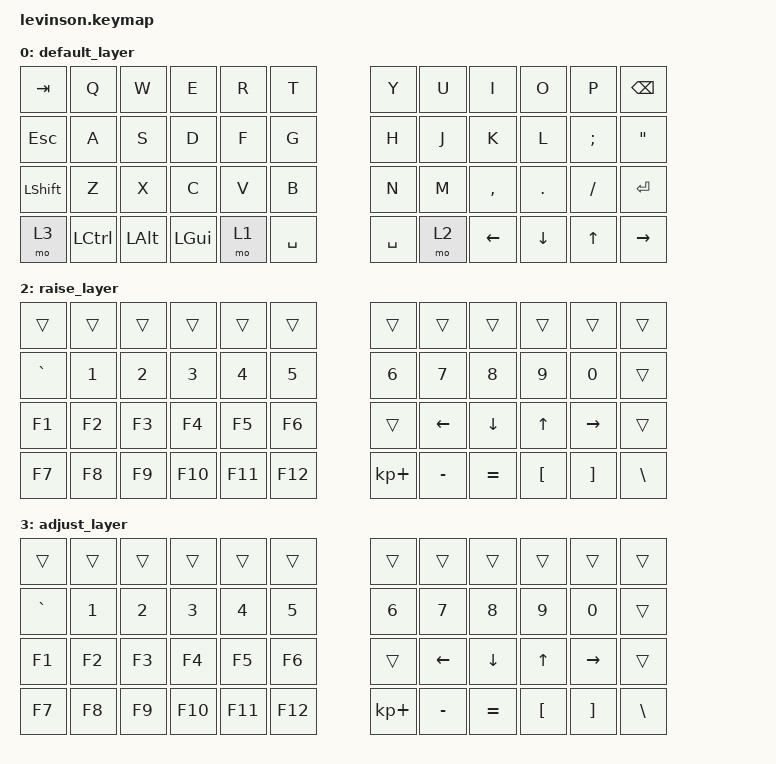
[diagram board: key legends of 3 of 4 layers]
/*
 * Copyright (c) 2020 The ZMK Contributors
 *
 * SPDX-License-Identifier: MIT
 */

#include <behaviors.dtsi>
#include <dt-bindings/zmk/keys.h>
#include <dt-bindings/zmk/bt.h>

/ {
	keymap {
		compatible = "zmk,keymap";

		default_layer {
// ------------------------------------------------------------------------------------------------------------
// |  TAB  |  Q  |  W  |  E   |  R   |  T   |                   |  Y   |  U    |  I    |  O   |   P   | BSPC  |
// |  ESC  |  A  |  S  |  D   |  F   |  G   |                   |  H   |  J    |  K    |  L   |   ;   |   "   |
// | SHIFT |  Z  |  X  |  C   |  V   |  B   |                   |  N   |  M    |  ,    |  .   |   /   | ENTER |
// | nan   | CTRL| ALT | GUI  | LOWER| SPACE|                   |SPACE | RAISE | LEFT  | DOWN |  UP   | RIGHT | 
			bindings = <
&kp TAB   &kp Q     &kp W    &kp E    &kp R    &kp T              &kp Y     &kp U  &kp I     &kp O   &kp P    &kp BSPC
&kp ESC   &kp A     &kp S    &kp D    &kp F    &kp G              &kp H     &kp J  &kp K     &kp L   &kp SEMI &kp DQT
&kp LSHFT &kp Z     &kp X    &kp C    &kp V    &kp B              &kp N     &kp M  &kp COMMA &kp DOT &kp FSLH &kp ENTER
&mo 3     &kp LCTRL &kp LALT &kp LGUI &mo 1    &kp SPACE          &kp SPACE &mo 2  &kp LEFT  &kp DOWN &kp UP  &kp RIGHT
			>;
		};

		lower_layer {
// ------------------------------------------------------------------------------------------------------------
// |       |  1  |  2  |   3  |   4  |   5  |                   |  6   |  7    |  8    |   9  |  0    |       |
// | BTCLR | BT1 | BT2 |  BT3 |  BT4 |  BT5 |                   | LEFT | DOWN  |  UP   | RIGHT|       |       |
// |  F1   |  F2 |  F3 |  F4  |  F5  |  F6  |                   |  F7  |  F8   |  F9   |  F10 |  F11  |  F12  |
// |   `   |  !  |  @  |  #   |  $   |  %   |                   |  ^   |  &    |  *    |  (   |   )   |   ~   |
// |       |     |     |      |      |      |                   |      |  _    |  +    |  {   |   }   |  "|"  |
			bindings = <
&trans     &kp N1       &kp N2       &kp N3       &kp N4       &kp N5                      &kp N6    &kp N7    &kp N8          &kp N9    &kp N0    &trans
&bt BT_CLR &bt BT_SEL 0 &bt BT_SEL 1 &bt BT_SEL 2 &bt BT_SEL 3 &bt BT_SEL 4                &kp LEFT  &kp DOWN  &kp UP          &kp RIGHT &trans    &trans
&kp F1     &kp F2       &kp F3       &kp F4       &kp F5       &kp F6                      &kp F7    &kp F8    &kp F9          &kp F10   &kp F11   &kp F12
&kp GRAVE  &kp EXCL     &kp AT       &kp HASH     &kp DOLLAR   &kp PRCNT                   &kp CARET &kp AMPS  &kp KP_MULTIPLY &kp LPAR  &kp RPAR  &kp TILDE
&trans     &trans       &trans       &trans       &trans       &trans                      &trans    &kp MINUS &kp KP_PLUS     &kp LBRC  &kp RBRC  &kp PIPE
			>;
		};

		raise_layer {
// ------------------------------------------------------------------------------------------------------------
// |       |     |     |      |      |      |                   |      |       |       |      |       |       |
// |   `   |  1  |  2  |  3   |  4   |  5   |                   |  6   |   7   |   8   |  9   |   0   |       |
// |   F1  |  F2 |  F3 |  F4  |  F5  |  F6  |                   |      |   <-  |   ^   |  v   |  ->   |       |
// |   F7  |  F8 |  F9 |  F10 |  F11 |  F12 |                   |  +   |   -   |   =   |  [   |   ]   |   \   |
			bindings = <
&trans    &trans &trans &trans  &trans  &trans                       &trans      &trans    &trans    &trans   &trans    &trans
&kp GRAVE &kp N1 &kp N2 &kp N3  &kp N4  &kp N5                       &kp N6      &kp N7    &kp N8    &kp N9   &kp N0    &trans
&kp F1    &kp F2 &kp F3 &kp F4  &kp F5  &kp F6                       &trans      &kp LEFT  &kp DOWN  &kp UP   &kp RIGHT &trans
&kp F7    &kp F8 &kp F9 &kp F10 &kp F11 &kp F12                      &kp KP_PLUS &kp MINUS &kp EQUAL &kp LBKT &kp RBKT  &kp BSLH
			>;
		};

		adjust_layer {
// ------------------------------------------------------------------------------------------------------------
// |       |     |     |      |      |      |                   |      |       |       |      |       |       |
// |   `   |  1  |  2  |  3   |  4   |  5   |                   |  6   |   7   |   8   |  9   |   0   |       |
// |   F1  |  F2 |  F3 |  F4  |  F5  |  F6  |                   |      |   <-  |   ^   |  v   |  ->   |       |
// |   F7  |  F8 |  F9 |  F10 |  F11 |  F12 |                   |  +   |   -   |   =   |  [   |   ]   |   \   |
			bindings = <
&trans    &trans &trans &trans  &trans  &trans                       &trans      &trans    &trans    &trans   &trans    &trans
&kp GRAVE &kp N1 &kp N2 &kp N3  &kp N4  &kp N5                       &kp N6      &kp N7    &kp N8    &kp N9   &kp N0    &trans
&kp F1    &kp F2 &kp F3 &kp F4  &kp F5  &kp F6                       &trans      &kp LEFT  &kp DOWN  &kp UP   &kp RIGHT &trans
&kp F7    &kp F8 &kp F9 &kp F10 &kp F11 &kp F12                      &kp KP_PLUS &kp MINUS &kp EQUAL &kp LBKT &kp RBKT  &kp BSLH
			>;
		};
	};
};
